# AT32UC3C0128C device description
Architecture: AVR32_UC3; Family: AVR UC3
Registers are 32-bit, read-write, reset 0x0 unless marked. A register's access mark holds for its fields unless they carry their own. Offsets are from the block's base; [hi:lo] are bit positions; {n}, {i} and the like mark numbered series; 'fields as' and 'values as' point back to an identical list.

## SCIF — System Control Interface
Instances: SCIF 0xffff0800
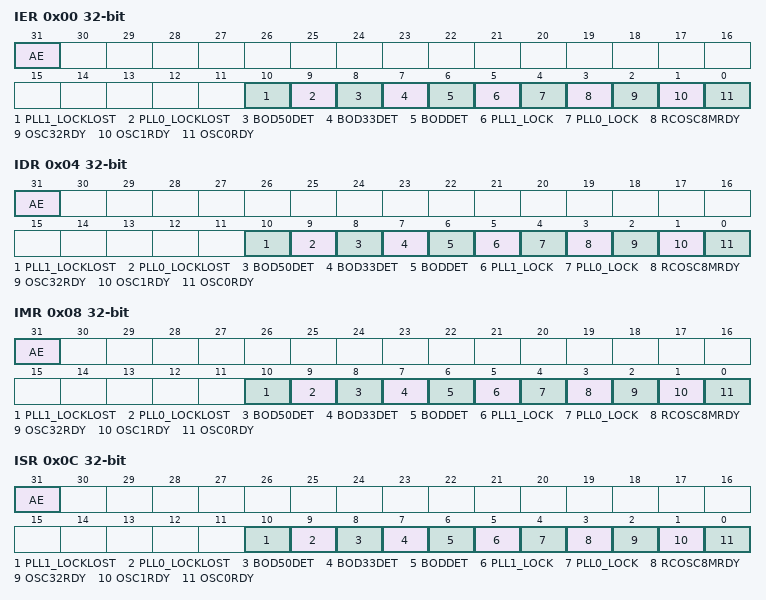
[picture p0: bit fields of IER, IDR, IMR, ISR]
0x00 IER wo — Interrupt Enable Register
  [31] AE, [10] PLL1_LOCKLOST, [9] PLL0_LOCKLOST, [8] BOD50DET, [7] BOD33DET, [6] BODDET, [5] PLL1_LOCK, [4] PLL0_LOCK, [3] RCOSC8MRDY, [2] OSC32RDY, [1] OSC1RDY, [0] OSC0RDY
0x04 IDR wo — Interrupt Disable Register
  fields as IER
0x08 IMR ro — Interrupt Mask Register
  fields as IER
0x0C ISR ro — Interrupt Status Register
  fields as IER
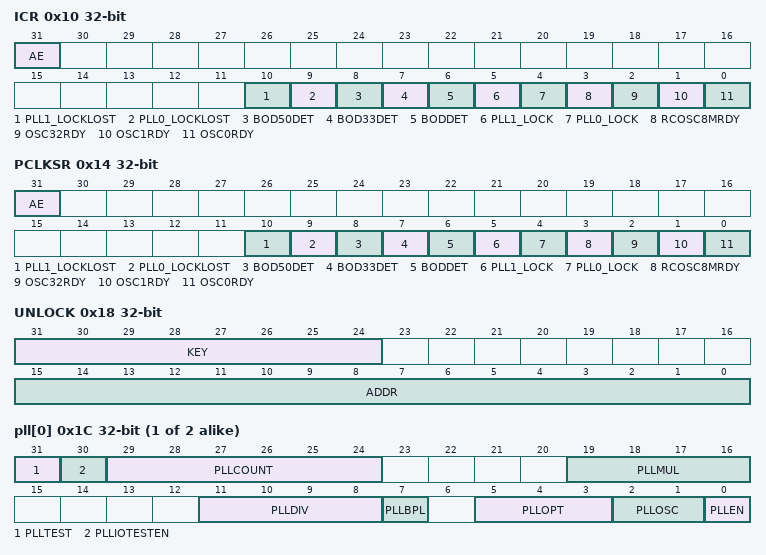
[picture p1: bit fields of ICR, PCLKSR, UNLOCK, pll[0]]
0x10 ICR wo — Interrupt Clear Register
  fields as IER
0x14 PCLKSR ro — Power and Clocks Status Register
  fields as IER
0x18 UNLOCK wo
  [31:24] KEY, [15:0] ADDR
{0x1C+4i} pll[{i}] (i=0..1) access not given
  [31] PLLTEST
  [30] PLLIOTESTEN — PLL IO Test Enable
  [29:24] PLLCOUNT
  [19:16] PLLMUL — PLL Multiply factor
  [11:8] PLLDIV — PLL Division factor
  [7] PLLBPL — PLL Bypass Lock
  [5:3] PLLOPT — PLL Option
  [2:1] PLLOSC — PLL Oscillator select
    0=OSC0; 1=OSC1; 2=RCOSC8
  [0] PLLEN — PLL Enable
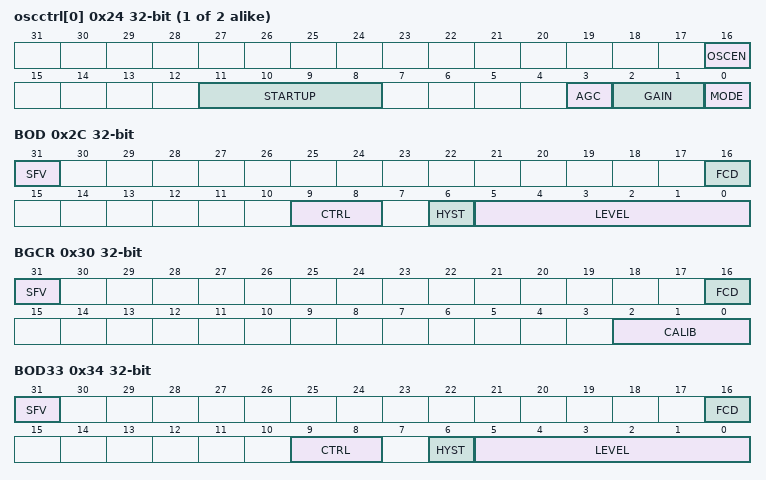
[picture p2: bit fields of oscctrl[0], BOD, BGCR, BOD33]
{0x24+4i} oscctrl[{i}] (i=0..1) access not given
  [16] OSCEN
  [11:8] STARTUP
  [3] AGC
  [2:1] GAIN
  [0] MODE
    0=EXT_CLOCK; 1=CRYSTAL_ACG; 2=CRYSTAL_NO_ACG
0x2C BOD — 1.8V BOD Control Register
  [31] SFV — Store final value
  [16] FCD — BOD Fuse calibration done
  [9:8] CTRL — BOD Control
    0=OFF1; 1=ENABLED_NORESET
  [6] HYST — BOD Hysteresis
  [5:0] LEVEL — BOD Level
0x30 BGCR — Bandgap Calibration Register
  [31] SFV — Store Final Value
  [16] FCD — Flash Calibration Done
  [2:0] CALIB — Calibration value
0x34 BOD33 — 3.3V BOD Control Register
  fields as BOD
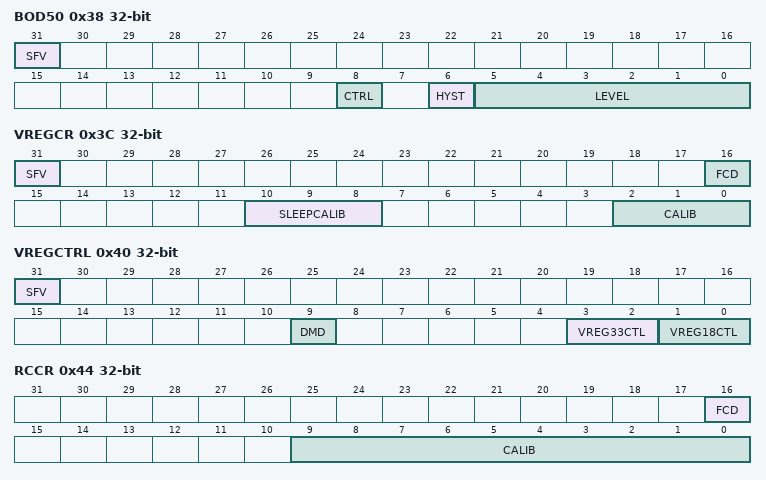
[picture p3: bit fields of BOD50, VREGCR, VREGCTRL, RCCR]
0x38 BOD50 — 5V BOD Control Register
  [31] SFV — Store final value
  [8] CTRL — BOD Control
    0=OFF1; 1=ENABLED_NORESET
  [6] HYST — BOD Hysteresis
  [5:0] LEVEL — BOD Level
0x3C VREGCR — Voltage Regulator Calibration Register
  [31] SFV — Store Final Value
  [16] FCD — Flash calibration done
  [10:8] SLEEPCALIB — Calibration value in sleep mode
  [2:0] CALIB — Calibration value
0x40 VREGCTRL — Voltage Regulator Control Register
  [31] SFV — Store Final Value
  [9] DMD — Deep Mode disable
  [3:2] VREG33CTL
    0=OpMode5v; 1=ByPassMode; 2=TestMode; 3=OpMode3v
  [1:0] VREG18CTL
    0=OpMode; 1=ByPassMode; 2=TestMode; 3=TestByPassMode
0x44 RCCR — RC Oscillator Calibration Register
  [16] FCD — Flash Calibration Done
  [9:0] CALIB — Calibration Value
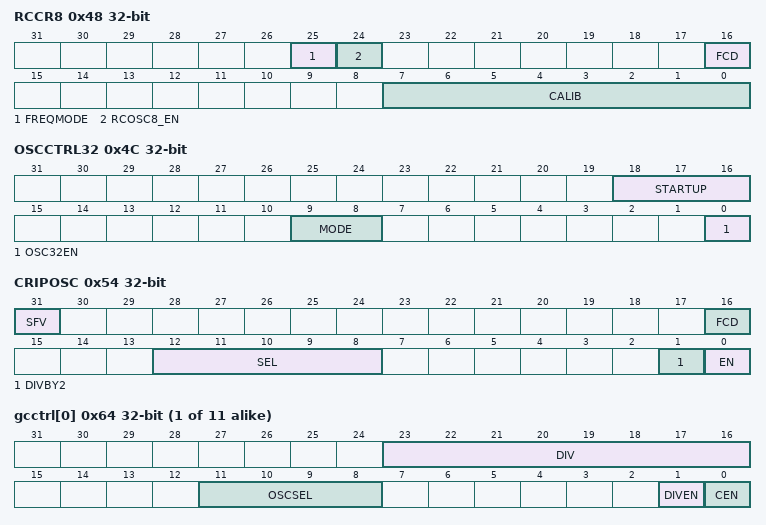
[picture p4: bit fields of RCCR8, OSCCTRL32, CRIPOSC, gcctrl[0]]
0x48 RCCR8 — 8MHz RC Oscillator Control Register
  [25] FREQMODE — 0=8Mhz ; 1=1Mhz
  [24] RCOSC8_EN — 0=OFF, 1=ON
  [16] FCD — Flash Calibration Done
  [7:0] CALIB — Calibration Value
0x4C OSCCTRL32 — Oscillator 32 Control Register
  [18:16] STARTUP — 32KHz Oscillator Startup Time
  [9:8] MODE — 32KHz Oscillator Mode
    0=EXT_CLOCK; 1=CRYSTAL_ACG; 2=CRYSTAL_NO_ACG
  [0] OSC32EN — Enable the 32KHz oscillator
0x50 TSENS — Temperature Sensor Register
  [0] EN — Enable
0x54 CRIPOSC — Critical Path Oscillator Configuration Register
  [31] SFV — Store Final Value
  [16] FCD — Fuse Calibration Done
  [12:8] SEL — Margin selection
  [1] DIVBY2
  [0] EN — CRIPOSC enable bit
0x58 RC120MCR — 120MHz RC Oscillator Control Register
  [0] EN — Enable bit
{0x5C+4i} gplp[{i}] (i=0..1) access not given
  [31:0] GPLP — General Purpose Low Power
{0x64+4i} gcctrl[{i}] (i=0..10) access not given
  [23:16] DIV — Division Factor
  [11:8] OSCSEL — Clock Select
  [1] DIVEN — Divide enable
  [0] CEN — Clock Enable
0x3C8 PLLVERSION ro reset 0x101 — PLL Interface Version Register
0x3CC OSCVERSION ro reset 0x110 — Oscillator Interface Version Register
0x3D0 BODVERSION ro reset 0x120 — 1.8V BOD Interface Version Register
0x3D4 BODBVERSION ro reset 0x200 — 3.3V and 5V BOD Interface Version Register
0x3D8 VREGVERSION ro reset 0x110 — Voltage Regulator Interface Version Register
0x3DC RCCRVERSION ro reset 0x110 — RC Oscillator Interface Version Register
0x3E0 RCCR8VERSION ro reset 0x100 — 8MHz RC Oscillator Interface Version Register
0x3E4 OSC32VERSION ro reset 0x100 — 32kHz RC Oscillator Interface Version Register
0x3E8 TSENSVERSION ro reset 0x100
0x3EC CRIPOSCVERSION ro reset 0x200
0x3F0 RC120MVERSION ro reset 0x110
0x3F4 GPLPVERSION ro reset 0x110
0x3F8 GCLKVERSION ro reset 0x101
0x3FC VERSION ro reset 0x102
